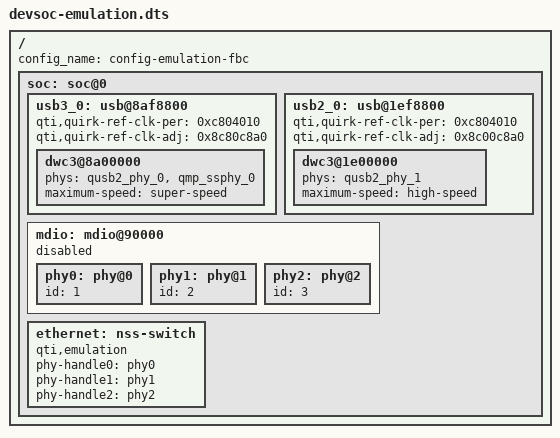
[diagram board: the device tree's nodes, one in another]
// SPDX-License-Identifier: GPL-2.0-only
/*
* Copyright (c) 2023-2024, Qualcomm Innovation Center, Inc. All rights reserved.
*/

#include "devsoc-default.dts"

/ {
	config_name = "config-emulation-fbc";

	soc: soc@0 {
		usb3_0: usb@8af8800 {
			qti,quirk-ref-clk-per = <0xc804010>;
			qti,quirk-ref-clk-adj = <0x8c80c8a0>;
			status = "okay";

			dwc3@8a00000 {
				phys = <&qusb2_phy_0>, <&qmp_ssphy_0>;
				phy-names = "usb2-phy", "usb3-phy";
				maximum-speed = "super-speed";
			};
		};

		usb2_0: usb@1ef8800 {
			qti,quirk-ref-clk-per = <0xc804010>;
			qti,quirk-ref-clk-adj = <0x8c00c8a0>;
			status = "okay";

			dwc3@1e00000 {
				phys = <&qusb2_phy_1>;
				phy-names = "usb2-phy";
				maximum-speed = "high-speed";
			};
		};

		mdio: mdio@90000 {
			pinctrl-names = "default";
			status = "disabled";

			phy0: phy@0 {
				id = <1>;
			};

			phy1: phy@1 {
				id = <2>;
			};

			phy2: phy@2 {
				id = <3>;
			};
		};

		ethernet: nss-switch {
			qti,emulation;
			pinctrl-names = "default";
			phy-handle0 = <&phy0>;
			phy-handle1 = <&phy1>;
			phy-handle2 = <&phy2>;
			status = "okay";
		};
	};
};
